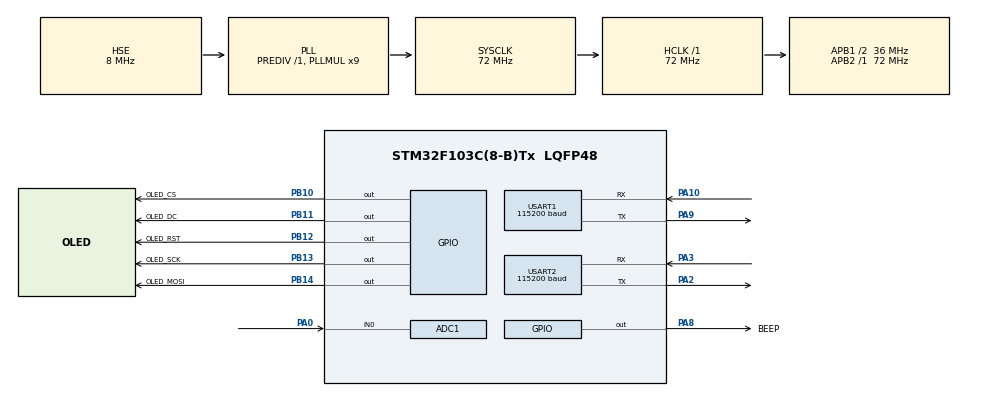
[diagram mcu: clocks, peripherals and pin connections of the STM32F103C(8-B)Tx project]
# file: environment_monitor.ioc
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ADC1.Channel-0\#ChannelRegularConversion=ADC_CHANNEL_0
ADC1.NbrOfConversionFlag=1
ADC1.Rank-0\#ChannelRegularConversion=1
ADC1.SamplingTime-0\#ChannelRegularConversion=ADC_SAMPLETIME_239CYCLES_5
ADC1.master=1
Mcu.Family=STM32F1
Mcu.Name=STM32F103C(8-B)Tx
Mcu.Package=LQFP48
NVIC.PriorityGroup=NVIC_PRIORITYGROUP_4
NVIC.USART2_IRQn=true\:0\:0\:false\:false\:true\:true\:true\:true
PA0-WKUP.Signal=ADCx_IN0
PA10.Mode=Asynchronous
PA10.Signal=USART1_RX
PA13.Mode=Serial_Wire
PA13.Signal=SYS_JTMS-SWDIO
PA14.Mode=Serial_Wire
PA14.Signal=SYS_JTCK-SWCLK
PA2.Mode=Asynchronous
PA2.Signal=USART2_TX
PA3.Mode=Asynchronous
PA3.Signal=USART2_RX
PA8.GPIO_Label=BEEP
PA8.GPIO_PuPd=GPIO_PULLDOWN
PA8.GPIO_Speed=GPIO_SPEED_FREQ_HIGH
PA8.Signal=GPIO_Output
PA9.Mode=Asynchronous
PA9.Signal=USART1_TX
PB10.GPIO_Label=OLED_CS
PB10.PinState=GPIO_PIN_SET
PB10.Signal=GPIO_Output
PB11.GPIO_Label=OLED_DC
PB11.PinState=GPIO_PIN_SET
PB11.Signal=GPIO_Output
PB12.GPIO_Label=OLED_RST
PB12.PinState=GPIO_PIN_SET
PB12.Signal=GPIO_Output
PB13.GPIO_Label=OLED_SCK
PB13.PinState=GPIO_PIN_SET
PB13.Signal=GPIO_Output
PB14.GPIO_Label=OLED_MOSI
PB14.PinState=GPIO_PIN_SET
PB14.Signal=GPIO_Output
PD0-OSC_IN.Mode=HSE-External-Oscillator
PD0-OSC_IN.Signal=RCC_OSC_IN
PD1-OSC_OUT.Mode=HSE-External-Oscillator
PD1-OSC_OUT.Signal=RCC_OSC_OUT
ProjectManager.HeapSize=0x200
ProjectManager.StackSize=0x400
ProjectManager.TargetToolchain=MDK-ARM V5.32
RCC.ADCPresc=RCC_ADCPCLK2_DIV6
RCC.AHBFreq_Value=72000000
RCC.APB1CLKDivider=RCC_HCLK_DIV2
RCC.APB1Freq_Value=36000000
RCC.APB1TimFreq_Value=72000000
RCC.APB2Freq_Value=72000000
RCC.APB2TimFreq_Value=72000000
RCC.HCLKFreq_Value=72000000
RCC.PLLMUL=RCC_PLL_MUL9
RCC.PLLSourceVirtual=RCC_PLLSOURCE_HSE
RCC.SYSCLKFreq_VALUE=72000000
RCC.SYSCLKSource=RCC_SYSCLKSOURCE_PLLCLK
RCC.USBFreq_Value=72000000
SH.ADCx_IN0.0=ADC1_IN0,IN0
USART1.BaudRate=115200
USART1.VirtualMode=VM_ASYNC
USART2.BaudRate=115200
USART2.VirtualMode=VM_ASYNC
board=custom

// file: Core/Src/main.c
/* USER CODE BEGIN Header */
/**
  ******************************************************************************
  * @file           : main.c
  * @brief          : Main program body
  ******************************************************************************
  */
/* USER CODE END Header */
/*
 * ============================================================================
 * 整体运行流程（写给完全没接触过STM32的同学）：
 *   1. 上电后先做硬件初始化：时钟、GPIO引脚(含蜂鸣器)、ADC1(接MQ2传感器)、两个串口
 *   2. 初始化调试日志、OLED屏幕、"环境监测"业务模块（连接MQ2传感器 + ESP-12F WiFi模块）
 *   3. 进入 while(1) 死循环，不断调用 EnvironmentMonitor_Process()：
 *      这个函数每次被调用都会检查"是否到了该读取传感器/上报数据/查收远程指令的时间"，
 *      如果到了就分别执行读取烟雾浓度、上报MQTT、处理平台下发的蜂鸣器控制指令。
 *   4. 整个程序没有操作系统（RTOS），是"轮询式"的单线程程序：一件事做完接着做下一件。
 * ============================================================================
 */
#include "main.h"
#include "adc.h"
#include "usart.h"
#include "gpio.h"

/* USER CODE BEGIN Includes */
#include "app_environment.h"
#include "debug_log.h"
#include "oled_display.h"
/* USER CODE END Includes */

void SystemClock_Config(void);

int main(void)
{

  /* MCU Configuration--------------------------------------------------------*/

  /* Reset of all peripherals, Initializes the Flash interface and the Systick. */
  HAL_Init();

  /* Configure the system clock */
  SystemClock_Config();

  /* Initialize all configured peripherals */
  MX_GPIO_Init();
  MX_ADC1_Init();
  MX_USART1_UART_Init();
  MX_USART2_UART_Init();
  /* USER CODE BEGIN 2 */
  /* 初始化调试串口(USART1)，后面所有DebugLog_Write打印的信息都通过它发到电脑串口终端 */
  DebugLog_Init();
  DebugLog_Write("\r\nBOOT: MQ-2 + ESP-12F monitor\r\n");
  DebugLog_Write("FW_REV: MQ2_SERVICE_DIAG_20260724_1148\r\n");
  DebugLog_Write("AUTH_PROFILE: DeviceName format, direct password preferred\r\n");
  DebugLog_Write("DEBUG UART: USART1 PA9/PA10, 115200 8N1\r\n");
  /* 初始化OLED屏幕，先显示烟雾浓度和蜂鸣器状态的占位符 */
  OLEDDisplay_Init();
  /* 初始化"环境监测"业务模块：传入ESP串口句柄和MQ2用的ADC句柄，
     这一步只初始化硬件和内部状态，还没有真正联网，联网动作在Process()里按需触发 */
  if (EnvironmentMonitor_Init(&huart2, &hadc1) != HAL_OK) {
    DebugLog_Write("ESP_INIT_FAIL: check ESP power, EN/RST, TX/RX and baud rate\r\n");
    Error_Handler();
  }
  DebugLog_Write("ESP_INIT_OK\r\n");
  /* USER CODE END 2 */

  /* Infinite loop */
  while (1)
  {

    /* USER CODE BEGIN 3 */
    /* 主循环：不断轮询"环境监测"模块，该函数内部自己控制节奏
       （多久读一次传感器、多久上报一次、多久发一次心跳、要不要查收远程指令），
       这里只需要一直调用它即可，不需要在main.c里写任何延时逻辑 */
    EnvironmentMonitor_Process();
  /* USER CODE END 3 */
}
}
void SystemClock_Config(void)
{
  RCC_OscInitTypeDef RCC_OscInitStruct = {0};
  RCC_ClkInitTypeDef RCC_ClkInitStruct = {0};
  RCC_PeriphCLKInitTypeDef PeriphClkInit = {0};

  /** Initializes the RCC Oscillators according to the specified parameters
  * in the RCC_OscInitTypeDef structure.
  */
  RCC_OscInitStruct.OscillatorType = RCC_OSCILLATORTYPE_HSE;
  RCC_OscInitStruct.HSEState = RCC_HSE_ON;
  RCC_OscInitStruct.HSEPredivValue = RCC_HSE_PREDIV_DIV1;
  RCC_OscInitStruct.HSIState = RCC_HSI_ON;
  RCC_OscInitStruct.PLL.PLLState = RCC_PLL_ON;
  RCC_OscInitStruct.PLL.PLLSource = RCC_PLLSOURCE_HSE;
  RCC_OscInitStruct.PLL.PLLMUL = RCC_PLL_MUL9;
  if (HAL_RCC_OscConfig(&RCC_OscInitStruct) != HAL_OK)
  {
    Error_Handler();
  }

  /** Initializes the CPU, AHB and APB buses clocks
  */
  RCC_ClkInitStruct.ClockType = RCC_CLOCKTYPE_HCLK|RCC_CLOCKTYPE_SYSCLK
                              |RCC_CLOCKTYPE_PCLK1|RCC_CLOCKTYPE_PCLK2;
  RCC_ClkInitStruct.SYSCLKSource = RCC_SYSCLKSOURCE_PLLCLK;
  RCC_ClkInitStruct.AHBCLKDivider = RCC_SYSCLK_DIV1;
  RCC_ClkInitStruct.APB1CLKDivider = RCC_HCLK_DIV2;
  RCC_ClkInitStruct.APB2CLKDivider = RCC_HCLK_DIV1;

  if (HAL_RCC_ClockConfig(&RCC_ClkInitStruct, FLASH_LATENCY_2) != HAL_OK)
  {
    Error_Handler();
  }
  PeriphClkInit.PeriphClockSelection = RCC_PERIPHCLK_ADC;
  PeriphClkInit.AdcClockSelection = RCC_ADCPCLK2_DIV6;
  if (HAL_RCCEx_PeriphCLKConfig(&PeriphClkInit) != HAL_OK)
  {
    Error_Handler();
  }
}

void Error_Handler(void)
{
  __disable_irq();
  while (1) { }
}
